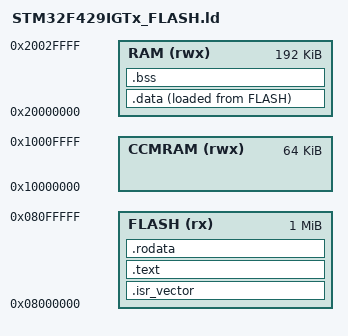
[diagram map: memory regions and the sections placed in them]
MEMORY
{
  FLASH (rx)  : ORIGIN = 0x08000000, LENGTH = 1024K
  RAM (rwx)   : ORIGIN = 0x20000000, LENGTH = 192K
  CCMRAM (rwx): ORIGIN = 0x10000000, LENGTH = 64K
}

ENTRY(Reset_Handler)

_estack = ORIGIN(RAM) + LENGTH(RAM);

SECTIONS
{
  .isr_vector :
  {
    . = ALIGN(4);
    KEEP(*(.isr_vector))
    . = ALIGN(4);
  } >FLASH

  .text :
  {
    . = ALIGN(4);
    *(.text)
    *(.text*)
    *(.glue_7)
    *(.glue_7t)
    *(.eh_frame)
    KEEP (*(.init))
    KEEP (*(.fini))
    . = ALIGN(4);
    _etext = .;
  } >FLASH

  .rodata :
  {
    . = ALIGN(4);
    *(.rodata)
    *(.rodata*)
    . = ALIGN(4);
  } >FLASH

  _sidata = LOADADDR(.data);

  .data :
  {
    . = ALIGN(4);
    _sdata = .;
    *(.data)
    *(.data*)
    . = ALIGN(4);
    _edata = .;
  } >RAM AT> FLASH

  . = ALIGN(4);
  _sbss = .;
  .bss :
  {
    *(.bss)
    *(.bss*)
    *(COMMON)
    . = ALIGN(4);
  } >RAM
  _ebss = .;
  end = .;

  /DISCARD/ :
  {
    libc.a ( * )
    libm.a ( * )
    libgcc.a ( * )
  }
}
